# PIC32CM5112SG00048 register map
Vendor: Microchip Technology; Series: PIC32CMSG00; File version: 0
CPU: CM23 r0p0, little endian, MPU, no FPU, 2 interrupt priority bits, 141 interrupts, 13 SAU regions
Registers are 32-bit, read-write, reset 0x0 unless marked. A register's access mark holds for its fields unless they carry their own. Offsets are from the block's base; [hi:lo] are bit positions; lines under a group give offsets from that group; {n}, {i} and the like mark numbered series.

## HMATRIX2 — HSB Matrix
Base 0x44010000
{0x0+4i} MCFG[{i}] (i=0..5) reset 0x2 — Master Configuration
  [2:0] ULBT — Undefined Length Burst Type
    0=INFINITE (Infinite Length); 1=SINGLE (Single Access); 2=FOUR_BEAT (Four Beat Burst); 3=EIGHT_BEAT (Eight Beat Burst); 4=SIXTEEN_BEAT (Sixteen Beat Burst)
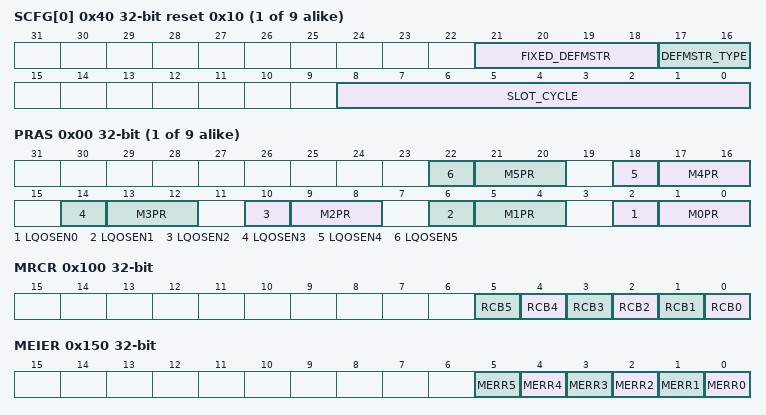
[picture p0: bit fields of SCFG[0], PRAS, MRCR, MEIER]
{0x40+4i} SCFG[{i}] (i=0..8) reset 0x10 — Slave Configuration
  [21:18] FIXED_DEFMSTR — Fixed Index of Default Master
  [17:16] DEFMSTR_TYPE — Default Master Type
    0=NO_DEFAULT (No Default Master. At the end of current slave access, if no other master request is pending, the slave is deconnected from all masters. This resusts in having a one cycle latency for the first transfer of a burst.); 1=LAST_DEFAULT (Last Default Master At the end of current slave access, if no other master request is pending, the slave stay connected with the last master havingaccessed it.This resusts in not having the one cycle latency when the last master re-trying access on the slave.); 2=FIXED_DEFAULT (Fixed Default Master At the end of current slave access, if no other master request is pending, the slave connects with fixed master which numberis in FIXED_DEFMSTR register.This resusts in not having the one cycle latency when the fixed master re-trying access on the slave.)
  [8:0] SLOT_CYCLE — Maximum Number of Allowed Cycles for a Burst
{0x80+8i} PRS[{i}] (i=0..8) group
  0x00 PRAS — Priority A for Slave
    [4n+2] LQOSEN{n} (n=0..5) — Latency Quality Of Service Enable for Master {n}
    [4n+1:4n] M{n}PR (n=0..5) — Master {n} Priority
0x100 MRCR — Master Remap Control
  [all] fields
    0=DIS (Disable remapped address decoding for master); 1=ENA (Enable remapped address decoding for master)
  [n] RCB{n} (n=0..5) — Remap Command Bit for Master {n}
{0x110+4i} SFR[{i}] (i=0..8) — Special Function
  [31:0] SFR — Special Function Register
0x150 MEIER wo — Master Error Interrupt Enable
  [n] MERR{n} (n=0..5) — Master {n} Access Error
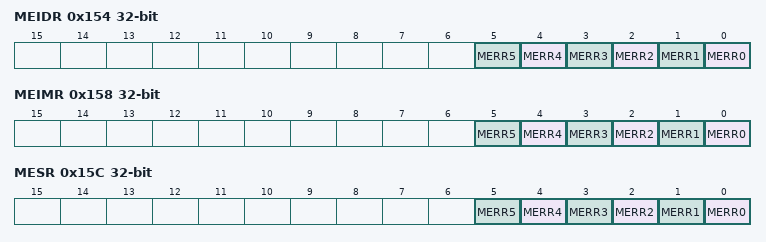
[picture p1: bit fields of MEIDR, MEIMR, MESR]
0x154 MEIDR wo — Master Error Interrupt Disable
  [n] MERR{n} (n=0..5) — Master {n} Access Error
0x158 MEIMR ro — Master Error Interrupt Mask
  [n] MERR{n} (n=0..5) — Master {n} Access Error
0x15C MESR ro write-1-clears — Master Error Status
  [n] MERR{n} (n=0..5) — Master {n} Access Error
{0x160+4i} MEAR[{i}] (i=0..5) ro — Master Error Address

## ICB — Implementation Control Block
Base 0xE000E000
Same registers: ICB_NS 0xE002E000
0x04 ICTR ro — Interrupt Controller Type Register
  [3:0] INTLINESNUM — Interrupt line set number
0x08 ACTLR — Auxiliary Control Register

## IDAU — Implementation Defined Attribution Unit
Base 0x44012000
0x00 CTRL wo — Control
  [31:16] CMD — Command Register
    0xA501=ENABLE (Module Enable); 0xA502=DISABLE (Module Disable); 0xA503=WLCK (Write Lock)
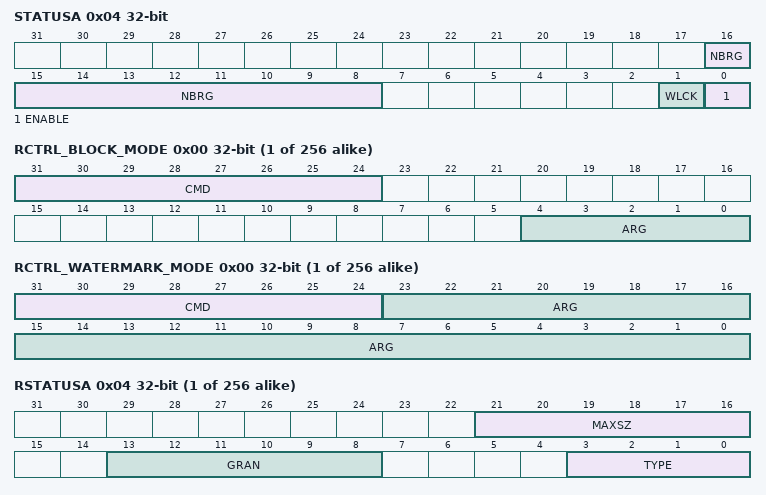
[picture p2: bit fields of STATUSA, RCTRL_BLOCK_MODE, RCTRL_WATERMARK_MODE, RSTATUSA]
0x04 STATUSA ro
  [16:8] NBRG — Number Of IDAU Regions
  [1] WLCK — Write Lock
  [0] ENABLE
0x08 STATUSB write-1-clears
  [0] CFGERR — Configuration Error
{0x1000+0x10*i} REGIONS[{i}] (i=0..255) group
  0x00 RCTRL_BLOCK_MODE wo — Region Control
    [31:24] CMD — Command
      90=CLRNONSEC (Clear IDAU region x Non-Secure State of block ARG (RSTATUSB[x].NONSEC[ARG]=0)); 91=SETNONSEC (Set IDAU region x Non-Secure State of block ARG (RSTATUSB[x].NONSEC[ARG]=1))
    [4:0] ARG — Command Argument (Block ID)
  0x00 RCTRL_WATERMARK_MODE wo (alternate view of RCTRL_BLOCK_MODE) — Region Control
    [31:24] CMD — Command
      92=WRSZ (Write IDAU region x Size (RSTATUSB[x].SIZE=ARG))
    [23:0] ARG — Command Argument (Watermark)
  0x04 RSTATUSA ro — Region Status A
    [21:16] MAXSZ — Command Argument Maximum Size
    [13:8] GRAN — Region Granularity
      0=GRAN_NA (Not Applicable); 5=GRAN_32B; 6=GRAN_64B; 7=GRAN_128B; 8=GRAN_256B; 9=GRAN_512B; 10=GRAN_1KB; 11=GRAN_2KB; 12=GRAN_4KB; 13=GRAN_8KB; 14=GRAN_16KB; 15=GRAN_32KB; 16=GRAN_64KB; 17=GRAN_128KB; 18=GRAN_256KB; 19=GRAN_512KB; 20=GRAN_1MB; 21=GRAN_2MB; 22=GRAN_4MB; 23=GRAN_8MB; 24=GRAN_16MB; 25=GRAN_32MB; 26=GRAN_64MB; 27=GRAN_128MB; 28=GRAN_256MB; 29=GRAN_512MB; 30=GRAN_1GB; 31=GRAN_2GB; 32=GRAN_4GB
    [3:0] TYPE — IDAU Region Type
      0=INVALID (Region is invalid); 1=SEC (Region is secure); 2=NONSEC (Region is non secure); 3=NONSEC_W (Region is non secure, the associated register group implements a watermark configuration); 4=SECnNONSEC_B (Region is either secure or non-secure, the associated register group implements a block configuration); 5=SECnNONSEC_L (Region is either secure or non-secure, configuration is linked to another IDAU region configuration bit (the linked configuration bit identification info is readable from the RSTATUSC register inside the same register group)); 6=NSC_W (Region is non-secure callable, the associated register group implements a watermark configuration); 7=EXEMPT_B (Region is exempt from security, the associated register group implements a block configuration)
  0x08 RSTATUSB_BLOCK_MODE ro — Region Status B
    [31:0] NONSEC — Block Based Region Non-Secure State
  0x08 RSTATUSB_WATERMARK_MODE ro (alternate view of RSTATUSB_BLOCK_MODE) — Region Status B
    [31:0] SIZE — Watermark Based Region Size in Bytes
  0x0C RSTATUSC_BLOCK_MODE ro — Region Status C
    [31:0] CST — Constant Block Configuration
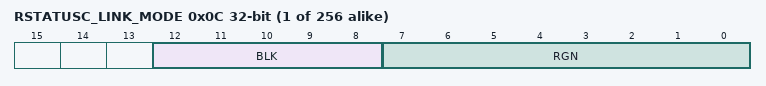
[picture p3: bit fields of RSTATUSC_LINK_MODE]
  0x0C RSTATUSC_LINK_MODE ro (alternate view of RSTATUSC_BLOCK_MODE) — Region Status C
    [12:8] BLK — Linked IDAU Region Block ID
    [7:0] RGN — Linked IDAU Region ID
